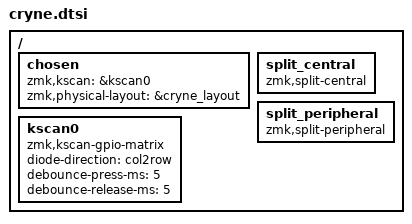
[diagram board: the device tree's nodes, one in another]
#include <dt-bindings/zmk/matrix_transform.h>
#include "cryne-layouts.dtsi"

/ {
  chosen {
    zmk,kscan = &kscan0;
    zmk,physical-layout = &cryne_layout;
  };

  split_central: split_central {
    compatible = "zmk,split-central";
  };

  split_peripheral: split_peripheral {
    compatible = "zmk,split-peripheral";
  };

  kscan0: kscan0 {
    compatible = "zmk,kscan-gpio-matrix";
    diode-direction = "col2row";
    // wakeup-source;  // DISABLED - can cause issues with some clones

    // Debounce settings (prevent accidental double-press)
    debounce-press-ms = <5>;
    debounce-release-ms = <5>;
  };
};
